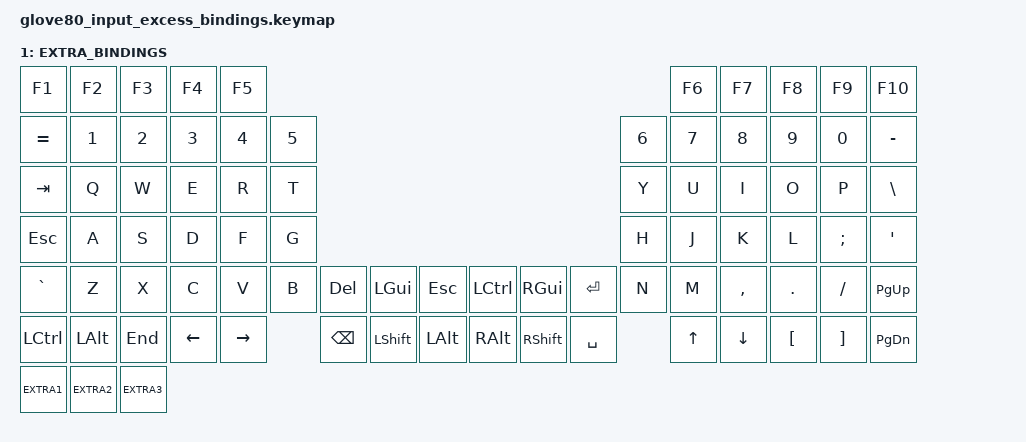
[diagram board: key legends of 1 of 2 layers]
/ {
    keymap {
        compatible = "zmk,keymap";
        BASE {
            bindings = <
   &kp F1          &kp F2      &kp F3        &kp F4       &kp F5                                                                                                                  &kp F6        &kp F7       &kp F8       &kp F9         &kp F10
   &kp EQUAL       &kp N1      &kp N2        &kp N3       &kp N4        &kp N5                                                                                       &kp N6       &kp N7        &kp N8       &kp N9       &kp N0         &kp MINUS
   &kp TAB         &kp Q       &ltl MOUSE W  &kp E        &kp R         &kp T                                                                                        &kp Y        &kp U         &kp I        &kp O        &kp P          &kp BSLH
   &kp ESC         &kp A       &hml LGUI S   &hml LALT D  &hml LCTRL F  &ltl NPAD G                                                                                  &ltr NPAD H  &hmr RCTRL J  &hmr RALT K  &hmr RGUI L  &kp SEMI       &kp SQT
   &kp GRAVE       &kp Z       &kp X         &kp C        &kp V         &kp B        &kp DEL   &kp LGUI   &kp ESC        &kp LCTRL             &kp RGUI   &kp RET    &kp N        &kp M         &kp COMMA    &kp DOT      &kp FSLH       &kp PG_UP
   &magic MAGIC 0  &lt 2 HOME  &kp END       &kp LEFT     &kp RIGHT                  &kp BSPC  &kp LSHFT  &ltl DEV LALT  &hmr &caps_word RALT  &kp RSHFT  &kp SPACE               &kp UP        &kp DOWN     &kp LBKT     &kp RBKT       &kp PG_DN
            >;
        };
        EXTRA_BINDINGS {
            bindings = <
   &kp F1          &kp F2      &kp F3        &kp F4       &kp F5                                                                                                                  &kp F6        &kp F7       &kp F8       &kp F9         &kp F10
   &kp EQUAL       &kp N1      &kp N2        &kp N3       &kp N4        &kp N5                                                                                       &kp N6       &kp N7        &kp N8       &kp N9       &kp N0         &kp MINUS
   &kp TAB         &kp Q       &kp W         &kp E        &kp R         &kp T                                                                                        &kp Y        &kp U         &kp I        &kp O        &kp P          &kp BSLH
   &kp ESC         &kp A       &kp S         &kp D        &kp F         &kp G                                                                                        &kp H        &kp J         &kp K        &kp L        &kp SEMI       &kp SQT
   &kp GRAVE       &kp Z       &kp X         &kp C        &kp V         &kp B        &kp DEL   &kp LGUI   &kp ESC        &kp LCTRL             &kp RGUI   &kp RET    &kp N        &kp M         &kp COMMA    &kp DOT      &kp FSLH       &kp PG_UP
   &kp LCTRL       &kp LALT    &kp END       &kp LEFT     &kp RIGHT                  &kp BSPC  &kp LSHFT  &kp LALT       &kp RALT              &kp RSHFT  &kp SPACE               &kp UP        &kp DOWN     &kp LBKT     &kp RBKT       &kp PG_DN
   &kp EXTRA1      &kp EXTRA2  &kp EXTRA3    // These extra bindings should cause a validation error
            >;
        };
    };
};
